# TLE986x register map
File version: 2.5
Registers are 32-bit, read-write, reset 0x0 unless marked. A register's access mark holds for its fields unless they carry their own. Offsets are from the block's base; [hi:lo] are bit positions; {n}, {i} and the like mark numbered series; 'fields as' and 'values as' point back to an identical list.

## ADC1
Base 0x40004000
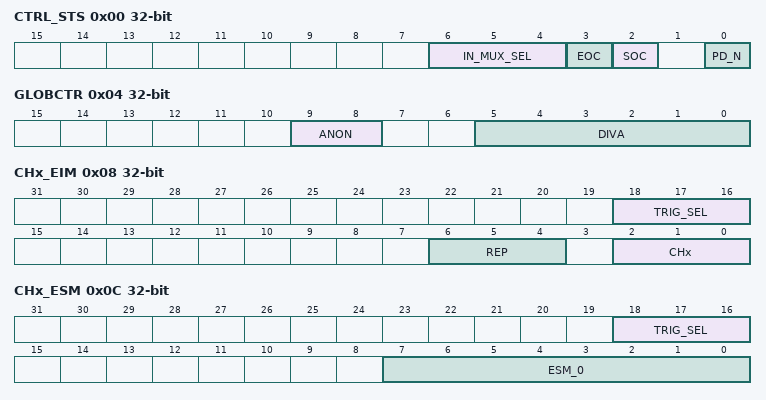
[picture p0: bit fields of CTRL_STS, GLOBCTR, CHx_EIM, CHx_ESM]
0x00 CTRL_STS access per field — ADC1 Control and Status Register
  [6:4] IN_MUX_SEL rw — Channel for software mode
    {v}=CH{v}_EN (Channel {v} enable) (v=0..7)
  [3] EOC ro — ADC1 End of Conversion (software mode)
    0=Pending (conversion still running); 1=Finished (conversion has finished)
  [2] SOC rw — ADC1 Start of Conversion (software mode)
    0=Disable (no conversion is started); 1=Enable (conversion is started)
  [0] PD_N rw — ADC1 Power Down Signal
    0=POWER DOWN (ADC1 is powered down); 1=ACTIVE (ADC1 is switched on)
0x04 GLOBCTR — Global Control Register
  [9:8] ANON — Analog Part Switched On
    0=OFF (ADC1 switched off); 1=S_STANDBY (Slow standby mode); 2=F_STANDBY (Fast standby mode); 3=NORMAL (Normal Operation)
  [5:0] DIVA — Divide Factor for the Analog internal clock: 0x00=Fadci = Fadc, 0x01=Fadci = Fadc/2, 0x02=Fadci = Fadc/3, 0x02=..., 0x3F=Fadci = Fadc/64,
0x08 CHx_EIM — Channel Settings Bits for Exceptional Interrupt Measurement
  [18:16] TRIG_SEL — Trigger selection for exceptional interrupt measurement (EIM)
    0=NONE; 1=COUT63; 2=GPT12_T6OUT; 3=GPT12_T3OUT; 4=T2 (t2_adc_trigger); 5=T21 (t21_adc_trigger); 6=CCU_6_INT
  [6:4] REP — Repeat count for exceptional interrupt measurement (EIM)
    0=Measurement; {v}=Measurements (v=1..7)
  [2:0] CHx — Channel set for exceptional interrupt measurement (EIM)
    {v}=CH{v}_EN (Channel {v} enable) (v=0..7)
0x0C CHx_ESM — Channel Settings Bits for Exceptional Sequence Measurement
  [18:16] TRIG_SEL — Trigger selection for exceptional interrupt measurement (ESM)
    values as CHx_EIM.TRIG_SEL
  [7:0] ESM_0 — Channel Sequence for Exceptional Sequence Measurement (ESM)
    1=CH0_EN (Channel 0 enable); 2=CH1_EN (Channel 1 enable); 4=CH2_EN (Channel 2 enable); 8=CH3_EN (Channel 3 enable); 16=CH4_EN (Channel 4 enable); 32=CH5_EN (Channel 5 enable); 64=CH6_EN (Channel 6 enable); 128=CH7_EN (Channel 7 enable)
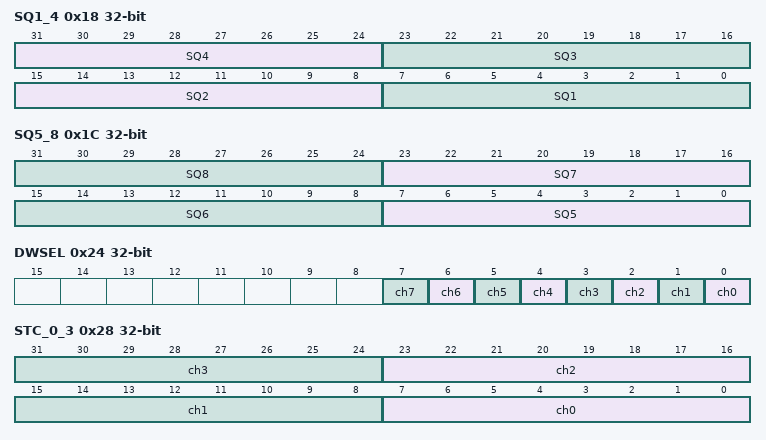
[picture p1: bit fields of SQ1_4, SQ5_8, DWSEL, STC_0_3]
0x18 SQ1_4 — Measurement Channel Enable Bits for Cycle 1 - 4
  [31:24] SQ4 — Sequence 4 channel enable
    values as CHx_ESM.ESM_0
  [23:16] SQ3 — Sequence 3 channel enable
    values as CHx_ESM.ESM_0
  [15:8] SQ2 — Sequence 2 channel enable
    values as CHx_ESM.ESM_0
  [7:0] SQ1 — Sequence 1 channel enable
    1=CH0_EN (Channel 0 enable); 2=CH1_EN (Channel 1 enable); 4=CH2_EN (Channel 2 enable); 8=CH3_EN (Channel 3 enable); 16=CH4_EN (Channel 4 enable); 32=CH5_EN (Channel 5 enable); 64=CH6_EN (Channel 6 enable); 128=CH7_EN (Channel 7enable)
0x1C SQ5_8 — Measurement Channel Enable Bits for Cycle 5 - 8
  [all] fields
    values as CHx_ESM.ESM_0
  [8n-33:8n-40] SQ{n} (n=5..8) — Sequence {n} channel enable
0x24 DWSEL — Measurement Channel Data Width Selection
  [all] fields
    0=10BIT (The result is 10 bits wide (bits 11 .. 2)); 1=8BIT (The result is 8 bits wide (bits 9 .. 4))
  [n] ch{n} (n=0..7) — Data Width channel {n}
0x28 STC_0_3 — Measurement Channel Sample Time Control 0 - 3
  [8n+7:8n] ch{n} (n=0..3) — Sample Time Control for Channel {n}
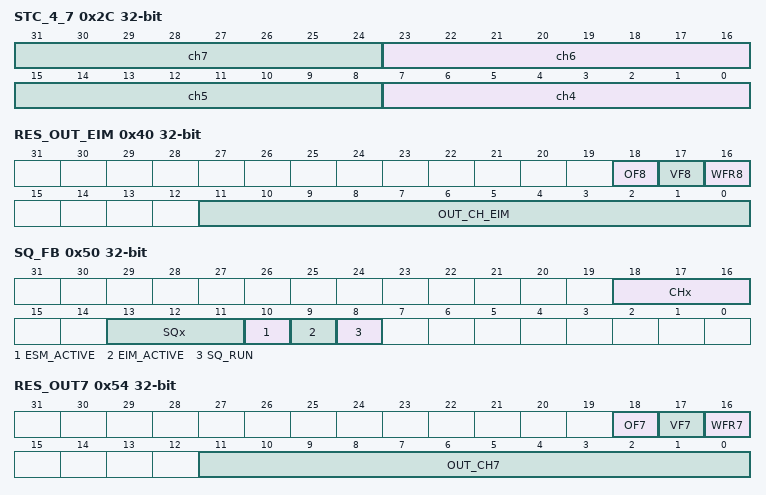
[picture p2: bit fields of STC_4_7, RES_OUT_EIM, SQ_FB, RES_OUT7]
0x2C STC_4_7 — Measurement Channel Sample Time Control 4 - 7
  [8n-25:8n-32] ch{n} (n=4..7) — Sample Time Control for Channel {n}
0x40 RES_OUT_EIM access per field (reset mask 0xFFFFF000) — ADC1 Output Channel EIM
  [18] OF8 ro — Overrun Flag
    0=NO OVERRUN (Result register not overwritten); 1=OVERRUN (Result register overwritten)
  [17] VF8 ro — Valid Flag
    0=NOT VALID (No new valid data available); 1=VALID (Result register contains valid data and has not yet been read)
  [16] WFR8 rw — Wait for Read Mode
    0=DISABLE (overwrite mode); 1=ENABLE (wait for read mode enabled)
  [11:0] OUT_CH_EIM ro — ADC1 output result value EIM
0x50 SQ_FB access per field — Sequencer Feedback Register
  [18:16] CHx ro — Current Channel
    {v}=CH{v} (Channel {v}) (v=0..7)
  [13:11] SQx ro — Current Active Sequence in Sequencer Mode
    {v}=SQ{v} (Sequence {v}) (v=0..7)
  [10] ESM_ACTIVE ro — ADC1 ESM active
    0=not active (ESM not active); 1=active (ESM active)
  [9] EIM_ACTIVE ro — ADC1 EIM active
    0=not active (EIM not active); 1=active (EIM active)
  [8] SQ_RUN rw — ADC1 Sequencer RUN
    0=SQ Stopped (Postprocessing Sequencer in stopped / Software mode); 1=SQ Running (Postprocessing Sequencer is running)
0x54 RES_OUT7 access per field (reset mask 0xFFFFF000) — ADC1 Output Channel 7
  [18] OF7 ro — Overrun Flag
    values as RES_OUT_EIM.OF8
  [17] VF7 ro — Valid Flag
    values as RES_OUT_EIM.VF8
  [16] WFR7 rw — Wait for Read Mode
    values as RES_OUT_EIM.WFR8
  [11:0] OUT_CH7 ro — ADC1 output result value channel 7
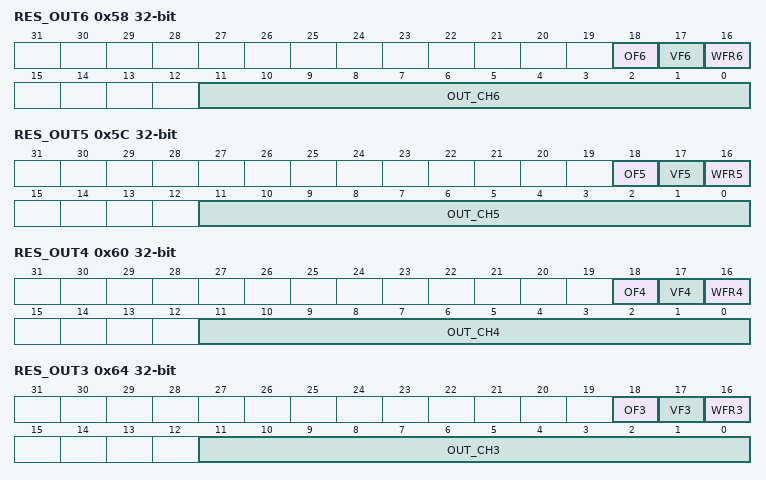
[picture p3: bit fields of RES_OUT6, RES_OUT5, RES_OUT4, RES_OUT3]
0x58 RES_OUT6 access per field (reset mask 0xFFFFF000) — ADC1 Output Channel 6
  [18] OF6 ro — Overrun Flag
    values as RES_OUT_EIM.OF8
  [17] VF6 ro — Valid Flag
    values as RES_OUT_EIM.VF8
  [16] WFR6 rw — Wait for Read Mode
    values as RES_OUT_EIM.WFR8
  [11:0] OUT_CH6 ro — ADC1 output result value channel 6
0x5C RES_OUT5 access per field (reset mask 0xFFFFF000) — ADC1 Output Channel 5
  [18] OF5 ro — Overrun Flag
    values as RES_OUT_EIM.OF8
  [17] VF5 ro — Valid Flag
    values as RES_OUT_EIM.VF8
  [16] WFR5 rw — Wait for Read Mode
    values as RES_OUT_EIM.WFR8
  [11:0] OUT_CH5 ro — ADC1 output result value channel 5
0x60 RES_OUT4 access per field (reset mask 0xFFFFF000) — ADC1 Output Channel 4
  [18] OF4 ro — Overrun Flag
    values as RES_OUT_EIM.OF8
  [17] VF4 ro — Valid Flag
    values as RES_OUT_EIM.VF8
  [16] WFR4 rw — Wait for Read Mode
    values as RES_OUT_EIM.WFR8
  [11:0] OUT_CH4 ro — ADC1 output result value channel 4
0x64 RES_OUT3 access per field (reset mask 0xFFFFF000) — ADC1 Output Channel 3
  [18] OF3 ro — Overrun Flag
    values as RES_OUT_EIM.OF8
  [17] VF3 ro — Valid Flag
    values as RES_OUT_EIM.VF8
  [16] WFR3 rw — Wait for Read Mode
    values as RES_OUT_EIM.WFR8
  [11:0] OUT_CH3 ro — ADC1 output result value channel 3
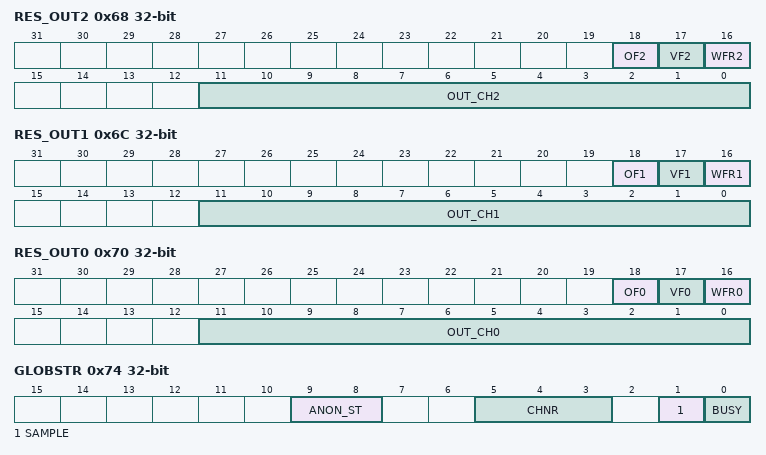
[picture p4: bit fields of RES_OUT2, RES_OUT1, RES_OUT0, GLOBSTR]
0x68 RES_OUT2 access per field (reset mask 0xFFFFF000) — ADC1 Output Channel 2
  [18] OF2 ro — Overrun Flag
    values as RES_OUT_EIM.OF8
  [17] VF2 ro — Valid Flag
    values as RES_OUT_EIM.VF8
  [16] WFR2 rw — Wait for Read Mode
    values as RES_OUT_EIM.WFR8
  [11:0] OUT_CH2 ro — ADC1 output result value channel 2
0x6C RES_OUT1 access per field (reset mask 0xFFFFF000) — ADC1 Output Channel 1
  [18] OF1 ro — Overrun Flag
    values as RES_OUT_EIM.OF8
  [17] VF1 ro — Valid Flag
    values as RES_OUT_EIM.VF8
  [16] WFR1 rw — Wait for Read Mode
    values as RES_OUT_EIM.WFR8
  [11:0] OUT_CH1 ro — ADC1 output result value channel 1
0x70 RES_OUT0 access per field (reset mask 0xFFFFF000) — ADC1 Output Channel 0
  [18] OF0 ro — Overrun Flag
    values as RES_OUT_EIM.OF8
  [17] VF0 ro — Valid Flag
    values as RES_OUT_EIM.VF8
  [16] WFR0 rw — Wait for Read Mode
    values as RES_OUT_EIM.WFR8
  [11:0] OUT_CH0 ro — ADC1 output reset value channel 0
0x74 GLOBSTR ro — Global Status Register
  [9:8] ANON_ST — Analog Part Switched On
    values as GLOBCTR.ANON
  [5:3] CHNR — Channel Number
  [1] SAMPLE — Sample Phase Indication
    0=IDLE (ADC1 is idle or converting); 1=ACTIVE (The Input signal is being sampled)
  [0] BUSY — Analog Part Busy
    0=IDLE (ADC1 idle); 1=ACTIVE (ADC1 Conversion is currently running)
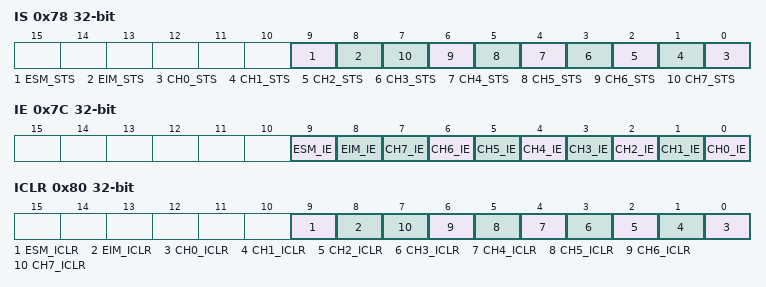
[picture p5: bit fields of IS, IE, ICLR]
0x78 IS ro — ADC1 Interrupt Status Register
  [9] ESM_STS — Exceptional Sequence Measurement (ESM) Status
    0=INACTIVE (No ESM has occurred); 1=ACTIVE (ESM occurred)
  [8] EIM_STS — Exceptional Interrupt Measurement (EIM) Status
    0=INACTIVE (No EIM occurred); 1=ACTIVE (EIM occurred)
  [n] CH{n}_STS (n=0..7) — ADC1 Channel {n} Interrupt Status
    0=INACTIVE (No Channel {n} Interrupt has occurred); 1=ACTIVE (Channel {n} Interrupt has occurred)
0x7C IE — ADC1 Interrupt Enable Register
  [all] fields
    0=DISABLED (Interrupt disabled); 1=ENABLED (Interrupt enabled)
  [9] ESM_IE — Exceptional Sequence Measurement (ESM) Interrupt Enable
  [8] EIM_IE — Exceptional Interrupt Measurement (EIM) Interrupt Enable
  [n] CH{n}_IE (n=0..7) — ADC1 Channel {n} Interrupt Enable
0x80 ICLR wo — ADC1 Interrupt Status Clear Register
  [9] ESM_ICLR — Exceptional Sequence Measurement (ESM) Status Clear
    0=INACTIVE (No ESM has cleared); 1=ACTIVE (ESM cleared)
  [8] EIM_ICLR — Exceptional Interrupt Measurement (EIM) Status Clear
    0=INACTIVE (No EIM cleared); 1=ACTIVE (EIM cleared)
  [n] CH{n}_ICLR (n=0..7) — ADC1 Channel {n} Interrupt Status Clear
    0=INACTIVE (interrupt status is not cleared); 1=ACTIVE (interrupt status is cleared)
